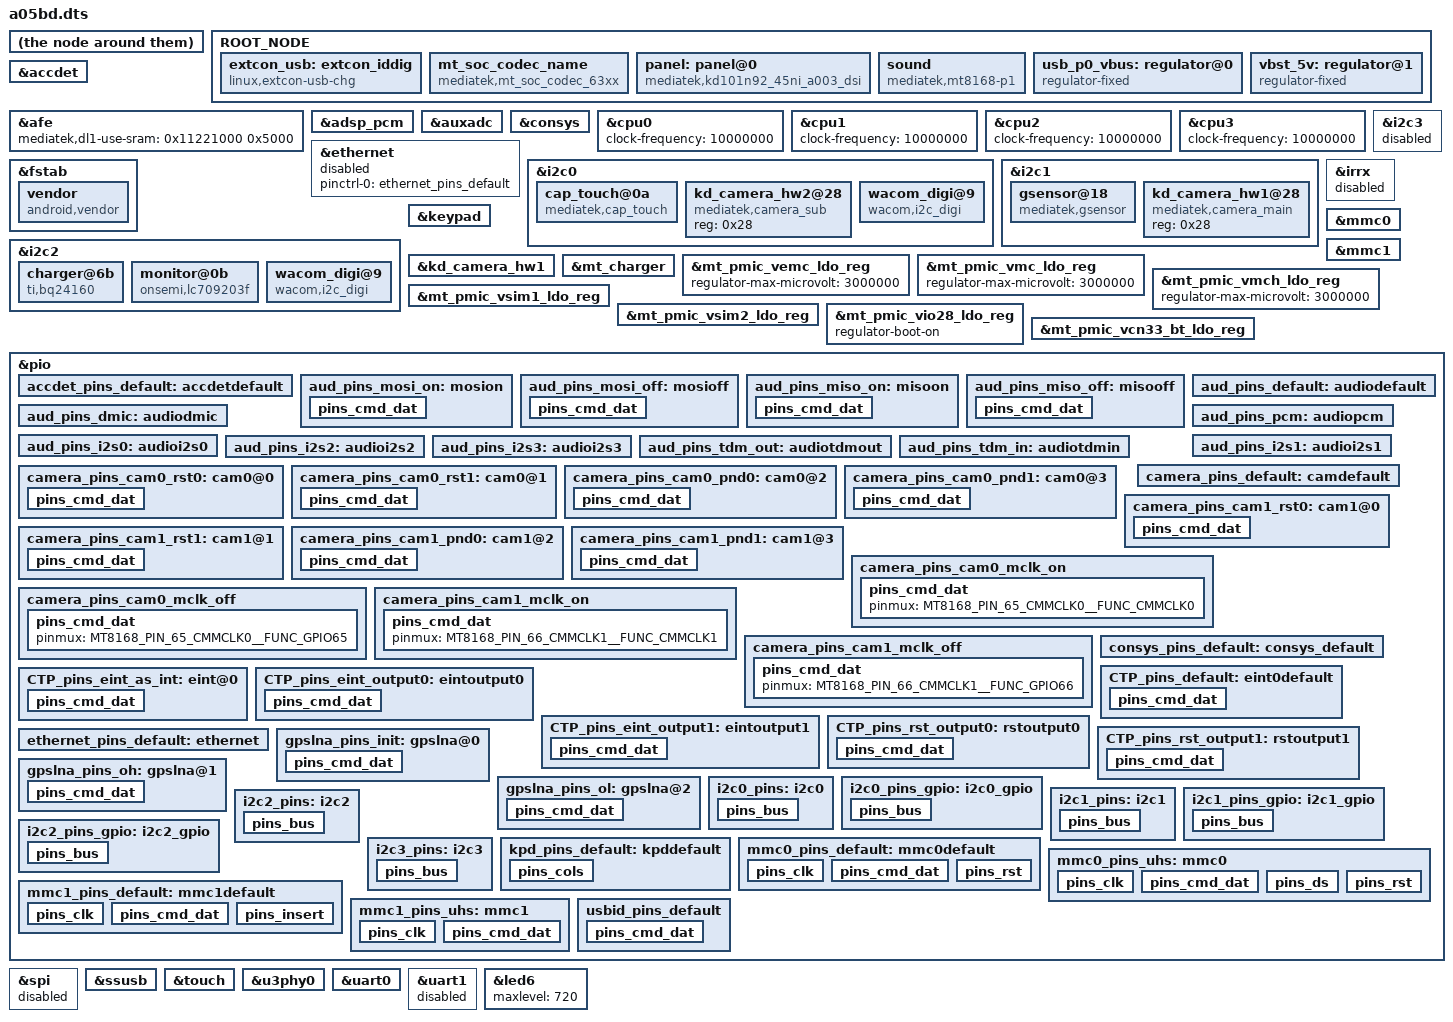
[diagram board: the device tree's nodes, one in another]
/*
 * Copyright (c) 2018 MediaTek Inc.
 *
 * This program is free software; you can redistribute it and/or modify
 * it under the terms of the GNU General Public License version 2 as
 * published by the Free Software Foundation.
 *
 * This program is distributed in the hope that it will be useful,
 * MERCHANTABILITY or FITNESS FOR A PARTICULAR PURPOSE.  See the
 * GNU General Public License for more details.
 */

#include <generated/autoconf.h>
/dts-v1/;

/plugin/;
#include <dt-bindings/clock/mt8168-clk.h>
#include <dt-bindings/interrupt-controller/irq.h>
#include <dt-bindings/interrupt-controller/arm-gic.h>
#include <dt-bindings/pinctrl/mt8168-pinfunc.h>
#include <dt-bindings/gpio/gpio.h>
#include <dt-bindings/phy/phy.h>
#define ROOT_NODE &odm

ROOT_NODE {
	extcon_usb: extcon_iddig {
		compatible = "linux,extcon-usb-chg";
		id-gpio = <&pio 17 GPIO_ACTIVE_HIGH>;
		pinctrl-names = "default";
		pinctrl-0 = <&usbid_pins_default>;
	};

	mt_soc_codec_name: mt_soc_codec_name {
		compatible = "mediatek,mt_soc_codec_63xx";
		use_hp_depop_flow = <0>; /* select 1: use, 0: not use */
		use_ul_260k = <0>; /* select 1: use, 0: not use */
	};

	panel: panel@0 {
		compatible = "mediatek,kd101n92_45ni_a003_dsi";
		gpio_lcd_rst = <&pio 20 0>;
		gpio_lcd_pwr = <&pio 127 0>;
		gpio_lcd_bl_en = <&pio 119 0>;
		/*reg-lcm-supply = <&mt_pmic_vsim1_ldo_reg>;*/
	};

	sound: sound {
		compatible = "mediatek,mt8168-p1";
		mediatek,platform = <&afe>;
		mediatek,adsp-platform = <&adsp_pcm>;
		pinctrl-names = "aud_mosi_on",
			"aud_mosi_off",
			"aud_miso_on",
			"aud_miso_off",
			"default",
			"aud_dmic",
			"aud_pcm",
			"aud_i2s0",
			"aud_i2s1",
			"aud_i2s2",
			"aud_i2s3",
			"aud_tdm_out",
			"aud_tdm_in";
		pinctrl-0 = <&aud_pins_mosi_on>;
		pinctrl-1 = <&aud_pins_mosi_off>;
		pinctrl-2 = <&aud_pins_miso_on>;
		pinctrl-3 = <&aud_pins_miso_off>;
		pinctrl-4 = <&aud_pins_default>;
		pinctrl-5 = <&aud_pins_dmic>;
		pinctrl-6 = <&aud_pins_pcm>;
		pinctrl-7 = <&aud_pins_i2s0>;
		pinctrl-8 = <&aud_pins_i2s1>;
		pinctrl-9 = <&aud_pins_i2s2>;
		pinctrl-10 = <&aud_pins_i2s3>;
		pinctrl-11 = <&aud_pins_tdm_out>;
		pinctrl-12 = <&aud_pins_tdm_in>;
		ext-amp1-gpio = <&pio 120 0>;
		ext-amp1en-gpio = <&pio 121 0>;
		/*ext-amp2-gpio = <&pio 69 0>;*/
		status = "okay";
	};

	usb_p0_vbus: regulator@0 {
		compatible = "regulator-fixed";
		regulator-name = "vbus";
		regulator-min-microvolt = <5000000>;
		regulator-max-microvolt = <5000000>;
		gpio = <&pio 16 GPIO_ACTIVE_HIGH>;
		enable-active-high;
	};

	vbst_5v: regulator@1 {
		compatible = "regulator-fixed";
		regulator-name = "vbst_5v";
		regulator-min-microvolt = <5000000>;
		regulator-max-microvolt = <5000000>;
		gpio = <&pio 18 GPIO_ACTIVE_HIGH>;
		enable-active-high;
	};
};

&accdet {
	accdet-mic-vol = <6>;
	headset-mode-setting = <0x500 0x500 1 0x1f0 0x800 0x800 0x20 0x44>;
	accdet-plugout-debounce = <1>;
	accdet-mic-mode = <1>;
	headset-eint-level-pol = <8>;
	/*headset-eint-level-pol = <4>;*/
	headset-three-key-threshold = <0 80 220 400>;
	headset-three-key-threshold-CDD = <0 121 192 600>;
	headset-four-key-threshold = <0 50 115 154 400>;
	pinctrl-names = "default", "state_eint_as_int";
	pinctrl-0 = <&accdet_pins_default>;
/*	pinctrl-1 = <&accdet_pins_eint_as_int>;*/
	status = "okay";
};

&afe {
	mediatek,dl1-use-sram = <0x11221000 0x5000>;
	status = "okay";
};

&adsp_pcm {
	status = "okay";
};

&auxadc {
	status = "okay";
};

&consys {
	pinctrl-names = "default", "gps_lna_state_init",
			"gps_lna_state_oh", "gps_lna_state_ol";
	pinctrl-0 = <&consys_pins_default>;
	pinctrl-1 = <&gpslna_pins_init>;
	pinctrl-2 = <&gpslna_pins_oh>;
	pinctrl-3 = <&gpslna_pins_ol>;
	status = "okay";
};

&cpu0 {
	clock-frequency = <10000000>;
};

&cpu1 {
	clock-frequency = <10000000>;
};

&cpu2 {
	clock-frequency = <10000000>;
};

&cpu3 {
	clock-frequency = <10000000>;
};

&ethernet {
	status = "disabled";
	pinctrl-names = "default";
	pinctrl-0 = <&ethernet_pins_default>;
};

&fstab {
	vendor {
		compatible = "android,vendor";
		dev = "/dev/block/platform/soc/11230000.mmc/by-name/vendor";
		type = "ext4";
		mnt_flags = "ro";
		fsmgr_flags = "wait,avb";
	};
};

&i2c0 {
	pinctrl-names = "default","gpio";
	pinctrl-0 = <&i2c0_pins>;
	pinctrl-1 = <&i2c0_pins_gpio>;
	clock-frequency = <370000>;
	status = "okay";
	scl-gpio = <&pio 58 0>;
	sda-gpio = <&pio 57 0>;
	
	cap_touch@0a {
		compatible = "mediatek,cap_touch";
		#address-cells = <1>;
		#size-cells = <0>;
		reg = <0x0a>;
		interrupt-parent = <&pio>;
		interrupts = <78 IRQ_TYPE_EDGE_FALLING>;
		int-gpio = <&pio 78 0>;
		rst-gpio = <&pio 79 0>;
		digi-gpio = <&pio 135 0>;
	};

	kd_camera_hw2@28 {
		compatible = "mediatek,camera_sub";
		#address-cells = <1>;
		#size-cells = <0>;
		reg = <0x28>;
	};

	wacom_digi@9 {
		compatible = "wacom,i2c_digi";
		#address-cells = <1>;
		#size-cells = <0>;
		reg = <0x09>;
		interrupt-parent = <&pio>;
		interrupts = <134 IRQ_TYPE_EDGE_FALLING>;
		int-gpio = <&pio 134 0>;
		rst-gpio = <&pio 133 0>;
		vdigi-supply = <&mt_pmic_vcn33_bt_ldo_reg>;
		wacom,swap_xy = <1>;
		wacom,invert_x = <0>;
		wacom,invert_y = <1>;
	};
};

&i2c1 {
	pinctrl-names = "default","gpio";
	pinctrl-0 = <&i2c1_pins>;
	pinctrl-1 = <&i2c1_pins_gpio>;
	clock-frequency = <370000>;
	status = "okay";
	scl-gpio = <&pio 60 0>;
	sda-gpio = <&pio 59 0>;

	gsensor@18 {
		compatible = "mediatek,gsensor";
		#address-cells = <1>;
		#size-cells = <0>;
		reg = <0x18>;
		status = "okay";
		i2c_num = <1>;
		i2c_addr = <0x18 0 0 0>;
		direction = <1>;
		power_id = <0xffff>;
		power_vol = <0>;
		firlen = <0>;
		is_batch_supported = <0>;
	};

	kd_camera_hw1@28 {
		compatible = "mediatek,camera_main";
		#address-cells = <1>;
		#size-cells = <0>;
		reg = <0x28>;
	};
};

&i2c2 {
	pinctrl-names = "default","gpio";
	pinctrl-0 = <&i2c2_pins>;
	pinctrl-1 = <&i2c2_pins_gpio>;
	clock-frequency = <370000>;
	status = "okay";
	scl-gpio = <&pio 62 0>;
	sda-gpio = <&pio 61 0>;

	charger@6b {
		compatible = "ti,bq24160";
		#address-cells = <1>;
		#size-cells = <0>;
		reg      = <0x6b>;
		ena-gpio = <&pio 125 0>;
		/*acdet-gpio = <&pio 39 0>;*/
		/*usbdet-gpio = <&pio 40 0>;*/
	};

	monitor@0b {
		compatible = "onsemi,lc709203f";
		#address-cells = <1>;
		#size-cells = <0>;
		reg      = <0x0b>;
		irq-gpio = <&pio 67 0>;
	};

	wacom_digi@9 {
		compatible = "wacom,i2c_digi";
		#address-cells = <1>;
		#size-cells = <0>;
		reg = <0x09>;
		interrupt-parent = <&pio>;
		interrupts = <134 IRQ_TYPE_EDGE_FALLING>;
		int-gpio = <&pio 134 0>;
		rst-gpio = <&pio 133 0>;
		vdigi-supply = <&mt_pmic_vcn33_bt_ldo_reg>;
		wacom,swap_xy = <1>;
		wacom,invert_x = <0>;
		wacom,invert_y = <1>;
	};
};

&i2c3 {
	pinctrl-names = "default";
	pinctrl-0 = <&i2c3_pins>;
	clock-frequency = <370000>;
	status = "disabled";
};

&irrx {
	status = "disabled";
};

&keypad {
	pinctrl-names = "default";
	pinctrl-0 = <&kpd_pins_default>;
	status = "okay";
	mediatek,kpd-key-debounce = <1024>;
	mediatek,kpd-sw-pwrkey = <116>;
	mediatek,kpd-hw-pwrkey = <1>;
	mediatek,kpd-sw-rstkey  = <114>;
	mediatek,kpd-hw-rstkey = <3>;
	mediatek,kpd-use-extend-type = <0>;
	/*HW Keycode [0~3] -> Linux Keycode*/
	mediatek,kpd-hw-map-num = <72>;
	mediatek,kpd-hw-init-map =
			<115 102 0 0 0 0 0 0 0 0 0 0 0
			 0 0 0 0 0 0 0 0 0 0 0 0 0 0 0 0 0 0 0 0 0 0 0 0
			 0 0 0 0 0 0 0 0 0 0 0 0 0 0 0 0 0 0 0 0 0 0 0 0
			 0 0 0 0 0 0 0 0 0 0 0 >;
	mediatek,kpd-pwrkey-eint-gpio = <0>;
	mediatek,kpd-pwkey-gpio-din  = <0>;
	mediatek,kpd-hw-dl-key0 = <0>;
	mediatek,kpd-hw-dl-key1 = <3>;
	mediatek,kpd-hw-dl-key2 = <1>;
	mediatek,kpd-hw-recovery-key = <0>;
	mediatek,kpd-hw-factory-key  = <3>;
};


&kd_camera_hw1 {
	/* main cam power supply */
	vcama-supply = <&mt_pmic_vcama_ldo_reg>;         /* AVDD */
	vcamd-supply = <&mt_pmic_vcamd_ldo_reg>;         /* DVDD */
	vcamio-supply = <&mt_pmic_vcamio_ldo_reg>;       /* DOVDD */

	/* sub cam power supply */
	vcama_sub-supply = <&mt_pmic_vcama_ldo_reg>;         /* AVDD */
	vcamd_sub-supply = <&mt_pmic_vcamd_ldo_reg>;         /* DVDD */
	vcamio_sub-supply = <&mt_pmic_vcamio_ldo_reg>;       /* DOVDD */

	pinctrl-names = "default",
			"cam0_rst0", "cam0_rst1", "cam0_pnd0", "cam0_pnd1",
			"cam1_rst0", "cam1_rst1", "cam1_pnd0", "cam1_pnd1",
			"cam0_mclk_on", "cam0_mclk_off",
			"cam1_mclk_on", "cam1_mclk_off";

	pinctrl-0 = <&camera_pins_default>;
	pinctrl-1 = <&camera_pins_cam0_rst0>;
	pinctrl-2 = <&camera_pins_cam0_rst1>;
	pinctrl-3 = <&camera_pins_cam0_pnd0>;
	pinctrl-4 = <&camera_pins_cam0_pnd1>;
	pinctrl-5 = <&camera_pins_cam1_rst0>;
	pinctrl-6 = <&camera_pins_cam1_rst1>;
	pinctrl-7 = <&camera_pins_cam1_pnd0>;
	pinctrl-8 = <&camera_pins_cam1_pnd1>;
	pinctrl-9 = <&camera_pins_cam0_mclk_on>;
	pinctrl-10 = <&camera_pins_cam0_mclk_off>;
	pinctrl-11 = <&camera_pins_cam1_mclk_on>;
	pinctrl-12 = <&camera_pins_cam1_mclk_off>;

	status = "okay";
};

&mmc0 {
	status = "okay";
	pinctrl-names = "default", "state_uhs";
	pinctrl-0 = <&mmc0_pins_default>;
	pinctrl-1 = <&mmc0_pins_uhs>;
	bus-width = <8>;
	max-frequency = <200000000>;
	cap-mmc-highspeed;
	mmc-hs200-1_8v;
	mmc-hs400-1_8v;
	cap-cqe;
	cap-cqe_dcmd;
	hs400-ds-delay = <0x12012>;
	vmmc-supply = <&mt_pmic_vemc_ldo_reg>;
	vqmmc-supply = <&mt_pmic_vio18_ldo_reg>;
	assigned-clocks = <&topckgen CLK_TOP_MSDC50_0_SEL>;
	assigned-clock-parents = <&topckgen CLK_TOP_MSDCPLL>;
	non-removable;
	no-sd;
	no-sdio;
};

&mmc1 {
	status = "okay";
	pinctrl-names = "default", "state_uhs";
	pinctrl-0 = <&mmc1_pins_default>;
	pinctrl-1 = <&mmc1_pins_uhs>;
	bus-width = <4>;
	max-frequency = <200000000>;
	cap-sd-highspeed;
	sd-uhs-sdr50;
	sd-uhs-sdr104;
	cd-gpios = <&pio 76 GPIO_ACTIVE_HIGH>;
	vmmc-supply = <&mt_pmic_vmch_ldo_reg>;
	vqmmc-supply = <&mt_pmic_vmc_ldo_reg>;
	no-mmc;
	no-sdio;
};

&mt_charger {
	extcon = <&extcon_usb>;
	interrupt-parent = <&pio>;
	interrupts = <126 IRQ_TYPE_EDGE_RISING>;
	chgint-gpios = <&pio 126 0>;
	chgled-gpio = <&pio 118 0>;
	acdet-gpio = <&pio 40 0>;
	usbdet-gpio = <&pio 39 0>;
	usbvbus-gpio = <&pio 16 0>;
	status = "okay";
};

&mt_pmic_vemc_ldo_reg {
	regulator-max-microvolt = <3000000>;
};

&mt_pmic_vmc_ldo_reg {
	regulator-max-microvolt = <3000000>;
};

&mt_pmic_vmch_ldo_reg {
	regulator-max-microvolt = <3000000>;
};

&mt_pmic_vsim1_ldo_reg {
	regulator-min-microvolt = <1800000>;
	regulator-max-microvolt = <1800000>;
	/*regulator-boot-on;*/
};

&mt_pmic_vsim2_ldo_reg {
	regulator-min-microvolt = <1800000>;
	regulator-max-microvolt = <1800000>;
	/*regulator-boot-on;*/
};

&mt_pmic_vio28_ldo_reg {
	regulator-boot-on;
};

&mt_pmic_vcn33_bt_ldo_reg {
	regulator-min-microvolt = <3300000>;
	regulator-max-microvolt = <3300000>;
/*	regulator-boot-on;*/
};


&pio {
	pinctrl-names = "default";

	accdet_pins_default: accdetdefault {
	};

	aud_pins_mosi_on: mosion {
		pins_cmd_dat {
		pinmux = <MT8168_PIN_49_AUD_CLK_MOSI__FUNC_AUD_CLK_MOSI>,
			 <MT8168_PIN_50_AUD_SYNC_MOSI__FUNC_AUD_SYNC_MOSI>,
			 <MT8168_PIN_51_AUD_DAT_MOSI0__FUNC_AUD_DAT_MOSI0>,
			 <MT8168_PIN_52_AUD_DAT_MOSI1__FUNC_AUD_DAT_MOSI1>;
		drive-strength = <MTK_DRIVE_6mA>;
		};
	};

	aud_pins_mosi_off: mosioff {
		pins_cmd_dat {
		pinmux = <MT8168_PIN_49_AUD_CLK_MOSI__FUNC_GPIO49>,
			 <MT8168_PIN_50_AUD_SYNC_MOSI__FUNC_GPIO50>,
			 <MT8168_PIN_51_AUD_DAT_MOSI0__FUNC_GPIO51>,
			 <MT8168_PIN_52_AUD_DAT_MOSI1__FUNC_GPIO52>;
		input-enable;
		bias-pull-down;
		drive-strength = <MTK_DRIVE_2mA>;
		};
	};

	aud_pins_miso_on: misoon {
		pins_cmd_dat {
		pinmux = <MT8168_PIN_53_AUD_CLK_MISO__FUNC_AUD_CLK_MISO>,
			 <MT8168_PIN_54_AUD_SYNC_MISO__FUNC_AUD_SYNC_MISO>,
			 <MT8168_PIN_55_AUD_DAT_MISO0__FUNC_AUD_DAT_MISO0>,
			 <MT8168_PIN_56_AUD_DAT_MISO1__FUNC_AUD_DAT_MISO1>;
		drive-strength = <MTK_DRIVE_6mA>;
		};
	};

	aud_pins_miso_off: misooff {
		pins_cmd_dat {
		pinmux = <MT8168_PIN_53_AUD_CLK_MISO__FUNC_GPIO53>,
			 <MT8168_PIN_54_AUD_SYNC_MISO__FUNC_GPIO54>,
			 <MT8168_PIN_55_AUD_DAT_MISO0__FUNC_GPIO55>,
			 <MT8168_PIN_56_AUD_DAT_MISO1__FUNC_GPIO56>;
		input-enable;
		bias-pull-down;
		drive-strength = <MTK_DRIVE_2mA>;
		};
	};

	aud_pins_default: audiodefault {
	};

	aud_pins_dmic: audiodmic {
	};

	aud_pins_pcm: audiopcm {
	};

	aud_pins_i2s0: audioi2s0 {
	};

	aud_pins_i2s1: audioi2s1 {
	};

	aud_pins_i2s2: audioi2s2 {
	};

	aud_pins_i2s3: audioi2s3 {
	};

	aud_pins_tdm_out: audiotdmout {
	};

	aud_pins_tdm_in: audiotdmin {
	};

	camera_pins_default: camdefault {
	};

	camera_pins_cam0_rst0: cam0@0 {
		pins_cmd_dat {
			pinmux = <MT8168_PIN_27_SPI_CK__FUNC_GPIO27>;
			slew-rate = <1>; /*direction 0:in, 1:out*/
			output-low;
		};
	};

	camera_pins_cam0_rst1: cam0@1 {
		pins_cmd_dat {
			pinmux = <MT8168_PIN_27_SPI_CK__FUNC_GPIO27>;
			slew-rate = <1>;
			output-high;
		};
	};

	camera_pins_cam0_pnd0: cam0@2 {
		pins_cmd_dat {
			pinmux = <MT8168_PIN_26_SPI_CS__FUNC_GPIO26>;
			slew-rate = <1>;
			output-low;
		};
	};

	camera_pins_cam0_pnd1: cam0@3 {
		pins_cmd_dat {
			pinmux = <MT8168_PIN_26_SPI_CS__FUNC_GPIO26>;
			slew-rate = <1>;
			output-high;
		};
	};

	camera_pins_cam1_rst0: cam1@0 {
		pins_cmd_dat {
			pinmux = <MT8168_PIN_29_SPI_MO__FUNC_GPIO29>;
			slew-rate = <1>; /*direction 0:in, 1:out*/
			output-low;
		};
	};

	camera_pins_cam1_rst1: cam1@1 {
		pins_cmd_dat {
			pinmux = <MT8168_PIN_29_SPI_MO__FUNC_GPIO29>;
			slew-rate = <1>;
			output-high;
		};
	};

	camera_pins_cam1_pnd0: cam1@2 {
		pins_cmd_dat {
			pinmux = <MT8168_PIN_28_SPI_MI__FUNC_GPIO28>;
			slew-rate = <1>;
			output-low;
		};
	};

	camera_pins_cam1_pnd1: cam1@3 {
		pins_cmd_dat {
			pinmux = <MT8168_PIN_28_SPI_MI__FUNC_GPIO28>;
			slew-rate = <1>;
			output-high;
		};
	};

	camera_pins_cam0_mclk_on: camera_pins_cam0_mclk_on {
		pins_cmd_dat {
			pinmux = <MT8168_PIN_65_CMMCLK0__FUNC_CMMCLK0>;
		};
	};

	camera_pins_cam0_mclk_off: camera_pins_cam0_mclk_off {
		pins_cmd_dat {
			pinmux = <MT8168_PIN_65_CMMCLK0__FUNC_GPIO65>;
		};
	};

	camera_pins_cam1_mclk_on: camera_pins_cam1_mclk_on {
		pins_cmd_dat {
			pinmux = <MT8168_PIN_66_CMMCLK1__FUNC_CMMCLK1>;
		};
	};

	camera_pins_cam1_mclk_off: camera_pins_cam1_mclk_off {
		pins_cmd_dat {
			pinmux = <MT8168_PIN_66_CMMCLK1__FUNC_GPIO66>;
		};
	};

	consys_pins_default: consys_default {
	};

	CTP_pins_default: eint0default {
		pins_cmd_dat {
			pinmux = <MT8168_PIN_78_CMHSYNC__FUNC_GPIO78>;
			slew-rate = <0>;
			bias-disable;
		};
	};

	CTP_pins_eint_as_int: eint@0 {
		pins_cmd_dat {
			pinmux = <MT8168_PIN_78_CMHSYNC__FUNC_GPIO78>;
			slew-rate = <0>;
			bias-disable;
		};
	};

	CTP_pins_eint_output0: eintoutput0 {
		pins_cmd_dat {
			pinmux = <MT8168_PIN_78_CMHSYNC__FUNC_GPIO78>;
			slew-rate = <1>;
			output-low;
		};
	};

	CTP_pins_eint_output1: eintoutput1 {
		pins_cmd_dat {
			pinmux = <MT8168_PIN_78_CMHSYNC__FUNC_GPIO78>;
			slew-rate = <1>;
			output-high;
		};
	};

	CTP_pins_rst_output0: rstoutput0 {
		pins_cmd_dat {
			pinmux = <MT8168_PIN_79_CMVSYNC__FUNC_GPIO79>;
			slew-rate = <1>;
			output-low;
		};
	};

	CTP_pins_rst_output1: rstoutput1 {
		pins_cmd_dat {
			pinmux = <MT8168_PIN_79_CMVSYNC__FUNC_GPIO79>;
			slew-rate = <1>;
			output-high;
		};
	};

	ethernet_pins_default: ethernet {
	};

	gpslna_pins_init: gpslna@0 {
		pins_cmd_dat {
			pinmux = <MT8168_PIN_77_CMDAT9__FUNC_GPIO77>;
			slew-rate = <0>;
			bias-disable;
			output-low;
		};
	};

	gpslna_pins_oh: gpslna@1 {
		pins_cmd_dat {
			pinmux = <MT8168_PIN_77_CMDAT9__FUNC_GPIO77>;
			slew-rate = <1>;
			output-high;
		};
	};

	gpslna_pins_ol: gpslna@2 {
		pins_cmd_dat {
			pinmux = <MT8168_PIN_77_CMDAT9__FUNC_GPIO77>;
			slew-rate = <1>;
			output-low;
		};
	};

	i2c0_pins: i2c0 {
		pins_bus {
			pinmux = <MT8168_PIN_57_SDA0__FUNC_SDA0_0>,
				 <MT8168_PIN_58_SCL0__FUNC_SCL0_0>;
			bias-pull-up = <MTK_PUPD_SET_R1R0_00>;
		};
	};

	i2c0_pins_gpio: i2c0_gpio {
		pins_bus {
			pinmux = <MT8168_PIN_57_SDA0__FUNC_GPIO57>,
				 <MT8168_PIN_58_SCL0__FUNC_GPIO58>;
			bias-pull-up = <MTK_PUPD_SET_R1R0_00>;
		};
	};

	i2c1_pins: i2c1 {
		pins_bus {
			pinmux = <MT8168_PIN_59_SDA1__FUNC_SDA1_0>,
				 <MT8168_PIN_60_SCL1__FUNC_SCL1_0>;
			bias-pull-up = <MTK_PUPD_SET_R1R0_00>;
		};
	};

	i2c1_pins_gpio: i2c1_gpio {
		pins_bus {
			pinmux = <MT8168_PIN_59_SDA1__FUNC_GPIO59>,
				 <MT8168_PIN_60_SCL1__FUNC_GPIO60>;
			bias-pull-up = <MTK_PUPD_SET_R1R0_00>;
		};
	};

	i2c2_pins: i2c2 {
		pins_bus {
			pinmux = <MT8168_PIN_61_SDA2__FUNC_SDA2_0>,
				 <MT8168_PIN_62_SCL2__FUNC_SCL2_0>;
			bias-pull-up = <MTK_PUPD_SET_R1R0_00>;
		};
	};

	i2c2_pins_gpio: i2c2_gpio {
		pins_bus {
			pinmux = <MT8168_PIN_61_SDA2__FUNC_GPIO61>,
				 <MT8168_PIN_62_SCL2__FUNC_GPIO62>;
			bias-pull-up = <MTK_PUPD_SET_R1R0_00>;
		};
	};

	i2c3_pins: i2c3 {
		pins_bus {
			pinmux = <MT8168_PIN_63_SDA3__FUNC_SDA3_0>,
				 <MT8168_PIN_64_SCL3__FUNC_SCL3_0>;
			bias-pull-up = <MTK_PUPD_SET_R1R0_00>;
//			drive-strength = <MTK_DRIVE_6mA>;
		};
	};

	kpd_pins_default: kpddefault {
		pins_cols {
			pinmux = <MT8168_PIN_24_KPCOL0__FUNC_KPCOL0>,
				 <MT8168_PIN_25_KPCOL1__FUNC_KPCOL1>;
			input-enable;
			bias-pull-up = <MTK_PUPD_SET_R1R0_01>;
		};
	};

	mmc0_pins_default: mmc0default {
		pins_clk {
			pinmux = <MT8168_PIN_99_MSDC0_CLK__FUNC_MSDC0_CLK>;
			bias-pull-down;
		};

		pins_cmd_dat {
			pinmux = <MT8168_PIN_103_MSDC0_DAT0__FUNC_MSDC0_DAT0>,
				 <MT8168_PIN_102_MSDC0_DAT1__FUNC_MSDC0_DAT1>,
				 <MT8168_PIN_101_MSDC0_DAT2__FUNC_MSDC0_DAT2>,
				 <MT8168_PIN_100_MSDC0_DAT3__FUNC_MSDC0_DAT3>,
				 <MT8168_PIN_96_MSDC0_DAT4__FUNC_MSDC0_DAT4>,
				 <MT8168_PIN_95_MSDC0_DAT5__FUNC_MSDC0_DAT5>,
				 <MT8168_PIN_94_MSDC0_DAT6__FUNC_MSDC0_DAT6>,
				 <MT8168_PIN_93_MSDC0_DAT7__FUNC_MSDC0_DAT7>,
				 <MT8168_PIN_98_MSDC0_CMD__FUNC_MSDC0_CMD>;
			input-enable;
			bias-pull-up;
		};

		pins_rst {
			pinmux = <MT8168_PIN_97_MSDC0_RSTB__FUNC_MSDC0_RSTB>;
			bias-pull-up;
		};
	};

	mmc0_pins_uhs: mmc0 {
		pins_clk {
			pinmux = <MT8168_PIN_99_MSDC0_CLK__FUNC_MSDC0_CLK>;
			drive-strength = <MTK_DRIVE_6mA>;
			bias-pull-down = <MTK_PUPD_SET_R1R0_01>;
		};

		pins_cmd_dat {
			pinmux = <MT8168_PIN_103_MSDC0_DAT0__FUNC_MSDC0_DAT0>,
				 <MT8168_PIN_102_MSDC0_DAT1__FUNC_MSDC0_DAT1>,
				 <MT8168_PIN_101_MSDC0_DAT2__FUNC_MSDC0_DAT2>,
				 <MT8168_PIN_100_MSDC0_DAT3__FUNC_MSDC0_DAT3>,
				 <MT8168_PIN_96_MSDC0_DAT4__FUNC_MSDC0_DAT4>,
				 <MT8168_PIN_95_MSDC0_DAT5__FUNC_MSDC0_DAT5>,
				 <MT8168_PIN_94_MSDC0_DAT6__FUNC_MSDC0_DAT6>,
				 <MT8168_PIN_93_MSDC0_DAT7__FUNC_MSDC0_DAT7>,
				 <MT8168_PIN_98_MSDC0_CMD__FUNC_MSDC0_CMD>;
			input-enable;
			drive-strength = <MTK_DRIVE_6mA>;
			bias-pull-up = <MTK_PUPD_SET_R1R0_01>;
		};

		pins_ds {
			pinmux = <MT8168_PIN_104_MSDC0_DSL__FUNC_MSDC0_DSL>;
			drive-strength = <MTK_DRIVE_6mA>;
			bias-pull-down = <MTK_PUPD_SET_R1R0_10>;
		};

		pins_rst {
			pinmux = <MT8168_PIN_97_MSDC0_RSTB__FUNC_MSDC0_RSTB>;
			bias-pull-up;
		};
	};

	mmc1_pins_default: mmc1default {
		pins_clk {
			pinmux = <MT8168_PIN_88_MSDC1_CLK__FUNC_MSDC1_CLK>;
			drive-strength = <MTK_DRIVE_4mA>;
			bias-pull-down = <MTK_PUPD_SET_R1R0_10>;
		};

		pins_cmd_dat {
			pinmux = <MT8168_PIN_89_MSDC1_DAT0__FUNC_MSDC1_DAT0>,
				 <MT8168_PIN_90_MSDC1_DAT1__FUNC_MSDC1_DAT1>,
				 <MT8168_PIN_91_MSDC1_DAT2__FUNC_MSDC1_DAT2>,
				 <MT8168_PIN_92_MSDC1_DAT3__FUNC_MSDC1_DAT3>,
				 <MT8168_PIN_87_MSDC1_CMD__FUNC_MSDC1_CMD>;
			input-enable;
			drive-strength = <MTK_DRIVE_4mA>;
			bias-pull-up = <MTK_PUPD_SET_R1R0_01>;
		};

		pins_insert {
			pinmux = <MT8168_PIN_76_CMDAT8__FUNC_GPIO76>;
			bias-pull-up;
		};
	};

	mmc1_pins_uhs: mmc1 {
		pins_clk {
			pinmux = <MT8168_PIN_88_MSDC1_CLK__FUNC_MSDC1_CLK>;
			drive-strength = <MTK_DRIVE_6mA>;
			bias-pull-down = <MTK_PUPD_SET_R1R0_10>;
		};

		pins_cmd_dat {
			pinmux = <MT8168_PIN_89_MSDC1_DAT0__FUNC_MSDC1_DAT0>,
				 <MT8168_PIN_90_MSDC1_DAT1__FUNC_MSDC1_DAT1>,
				 <MT8168_PIN_91_MSDC1_DAT2__FUNC_MSDC1_DAT2>,
				 <MT8168_PIN_92_MSDC1_DAT3__FUNC_MSDC1_DAT3>,
				 <MT8168_PIN_87_MSDC1_CMD__FUNC_MSDC1_CMD>;
			input-enable;
			drive-strength = <MTK_DRIVE_6mA>;
			bias-pull-up = <MTK_PUPD_SET_R1R0_01>;
		};
	};

	usbid_pins_default: usbid_pins_default {
		pins_cmd_dat {
			pinmux = <MT8168_PIN_17_GPIO17__FUNC_GPIO17>;
			input-enable;
			slew-rate = <0>;
			bias-pull-up;
		};
	};
};

&spi {
	status = "disabled";
};

&ssusb {
	phys = <&u2port0 PHY_TYPE_USB2>;
	vusb33-supply = <&mt_pmic_vusb33_ldo_reg>;
	vbus-supply = <&usb_p0_vbus>;
	vbst_5v-supply = <&vbst_5v>;
	extcon = <&extcon_usb>;
	dr_mode = "otg";
	status="okay";
};

&touch {
	vtouch-supply = <&mt_pmic_vcn33_bt_ldo_reg>;
	tpd-resolution = <800 1280>;
	use-tpd-button = <0>;
	tpd-key-num = <3>;
	tpd-key-local= <139 172 158 0>;
	tpd-key-dim-local = <90 883 100 40 230 883
		100 40 370 883 100 40 0 0 0 0>;
	tpd-max-touch-num = <5>;
	tpd-filter-enable = <1>;
	tpd-filter-pixel-density = <124>;
	tpd-filter-custom-prameters = <0 0 0 0 0 0 0 0 0 0 0 0>;
	tpd-filter-custom-speed = <0 0 0>;
	pinctrl-names = "default", "state_eint_as_int",
		"state_eint_output0", "state_eint_output1",
		"state_rst_output0", "state_rst_output1";
	pinctrl-0 = <&CTP_pins_default>;
	pinctrl-1 = <&CTP_pins_eint_as_int>;
	pinctrl-2 = <&CTP_pins_eint_output0>;
	pinctrl-3 = <&CTP_pins_eint_output1>;
	pinctrl-4 = <&CTP_pins_rst_output0>;
	pinctrl-5 = <&CTP_pins_rst_output1>;
	status = "okay";
};

&u3phy0 {
	status="okay";
};

&uart0 {
	status="okay";
};

&uart1 {
	status="disabled";
};

&led6 {
	maxlevel = <720>;
};
